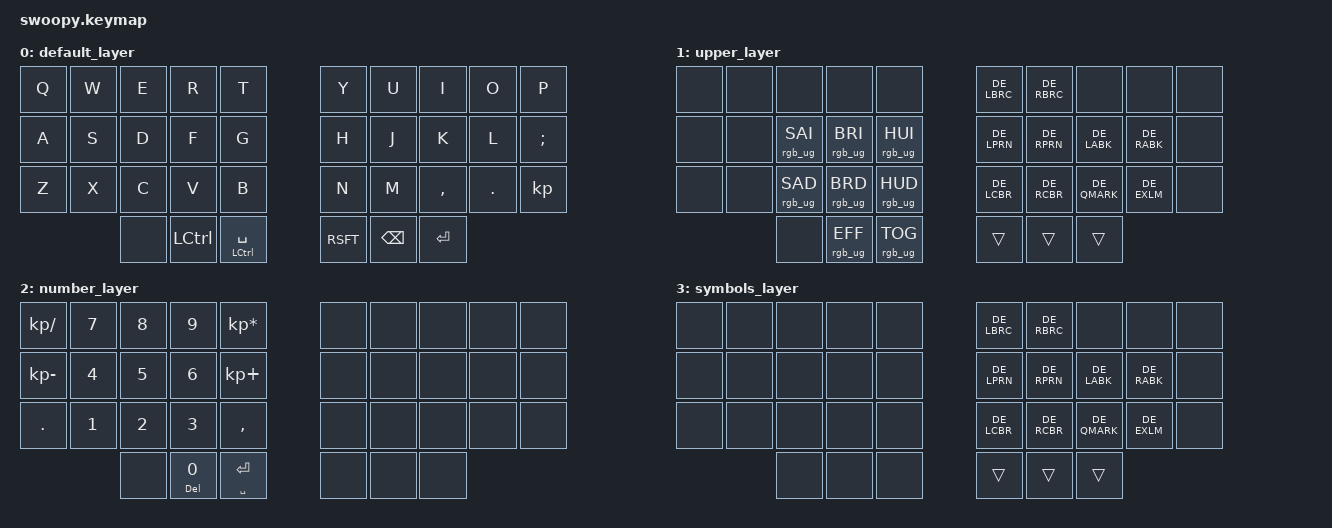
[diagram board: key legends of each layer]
#include <behaviors.dtsi>
#include <dt-bindings/zmk/keys.h>
#include <dt-bindings/zmk/bt.h>
#include <dt-bindings/zmk/rgb.h>


#define DE_LPRN LS(N8)      // (
#define DE_RPRN LS(N9)      // )
#define DE_LBRC RA(N8)      // [
#define DE_RBRC RA(N9)      // ]
#define DE_LCBR RA(N7)      // {
#define DE_RCBR RA(N0)      // }
#define DE_LABK NON_US_BSLH // 
#define DE_RABK LS(NON_US_BSLH) // >
#define DE_QMARK LS(MINUS)    // ?
#define DE_EXLM  LS(N1)       // !

/ {
    keymap {
        compatible = "zmk,keymap";

        

        default_layer {
            bindings = <
                &kp Q    &kp W    &kp E    &kp R    &kp T               &kp Y    &kp U    &kp I    &kp O    &kp P
                &kp A    &kp S    &kp D    &kp F    &kp G               &kp H    &kp J    &kp K    &kp L    &kp SEMI
                &kp Z    &kp X    &kp C    &kp V    &kp B               &kp N    &kp M    &kp COMMA &kp DOT &kp 
                                  &none    &kp LCTRL  &mt LCTRL SPC     &kp RSFT   &kp BSPC    &kp RET
            >;
            sensor-bindings = <&inc_dec_kp PG_UP PG_DN>;
        };

        upper_layer {
            bindings = <
                &none   &none   &none   &none   &none                                       &kp DE_LBRC   &kp DE_RBRC    &none     &none     &none
                &none   &none   &rgb_ug RGB_SAI   &rgb_ug RGB_BRI   &rgb_ug RGB_HUI         &kp DE_LPRN   &kp DE_RPRN    &kp DE_LABK   &kp DE_RABK &none
                &none   &none   &rgb_ug RGB_SAD   &rgb_ug RGB_BRD   &rgb_ug RGB_HUD         &kp DE_LCBR   &kp DE_RCBR    &kp DE_QMARK     &kp DE_EXLM     &none
                                &none   &rgb_ug RGB_EFF   &rgb_ug RGB_TOG                   &trans  &trans   &trans
            >;
        };

        number_layer {
            bindings = <
                &kp KP_DIVIDE   &kp N7   &kp N8   &kp N9    &kp KP_MULTIPLY     &none   &none    &none     &none     &none
                &kp KP_MINUS    &kp N4   &kp N5   &kp N6    &kp KP_PLUS         &none   &none    &none     &none     &none
                &kp DOT         &kp N1   &kp N2   &kp N3    &kp COMMA           &none   &none    &none     &none     &none
                                         &none    &mt DEL N0 &mt SPC RET        &none   &none    &none         
            >;
        };

        symbols_layer {
            bindings = <
                &none   &none   &none   &none   &none                    &kp DE_LBRC   &kp DE_RBRC    &none     &none     &none
                &none   &none   &none   &none   &none                    &kp DE_LPRN   &kp DE_RPRN    &kp DE_LABK   &kp DE_RABK &none
                &none   &none   &none   &none   &none                    &kp DE_LCBR   &kp DE_RCBR    &kp DE_QMARK     &kp DE_EXLM     &none
                                &none   &none   &none                    &trans  &trans   &trans
            >;
        };

        extra1 {
            status = "reserved";
        };

        extra2 {
            status = "reserved";
        };

        extra3 {
            status = "reserved";
        };

        extra4 {
            status = "reserved";
        };
    };
    combos {
        compatible = "zmk,combos";

        combo_lower {
            timeout-ms = <50>;
            key-positions = <32 24>;
            bindings = <&to 0>;
        };

        combo_upper {
            timeout-ms = <50>;
            key-positions = <32 14>;
            bindings = <&to 1>;
        };

        combo_klam {
            timeout-ms = <50>;
            key-positions = <32 4>;
            bindings = <&to 2>;
        };

        combo_zmkstudio {
            timeout-ms = <50>;
            key-positions = <4 5>;
            bindings = <&studio_unlock>;
        };
    };

    behaviors {
        qm_excl: question_exclamation {
            compatible = "zmk,behavior-mod-morph";
            #binding-cells = <0>;
            bindings = <&kp QMARK>, <&kp EXCL>;
            mods = <(MOD_LSFT | MOD_RSFT)>;
        };
    };
};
